# FM33FH0XX register map
File version: 1.0
CPU: SC000 r1p0, little endian, no MPU, no FPU, 3 interrupt priority bits
Registers are 32-bit, read-write, reset 0x0 unless marked. A register's access mark holds for its fields unless they carry their own. Offsets are from the block's base; lines under a group give offsets from that group; [hi:lo] are bit positions; {n}, {i} and the like mark numbered series; 'fields as' and 'values as' point back to an identical list; <NAME> marks a mode.

## Memory map
0x40000000 SCU size 0xC — SCU module information
0x40000400 DMA size 0x314 — DMA module information
0x40000800 QSPI size 0x30 — QSPI module information
0x40000C00 GPIOA size 0x30 — GPIOA module information
0x40000C40 GPIOB size 0x30 — GPIOB module information
0x40000C80 GPIOC size 0x30 — GPIOC module information
0x40000CC0 GPIOD size 0x30 — GPIOD module information
0x40000D00 GPIOE size 0x30 — GPIOE module information
0x40000D40 GPIOF size 0x30 — GPIOF module information
0x40000D80 GPIOG size 0x30 — GPIOG module information
0x40000DC0 GPIOH size 0x30 — GPIOH module information
0x40000E40 GPIO_COMMON size 0xE0 — GPIO module information
0x40001000 FLS size 0xA0 — FLS module information
0x40002000 PMU size 0x54 — PMU module information
0x40002400 CMU size 0x88 — CMU module information
0x40002800 RMU size 0x24 — RMU module information
0x40002C00 SFU size 0x10 — SFU module information
0x40010000 TSI size 0x80 — TSI module information
0x40010400 LPUART size 0x1C — LPUART module information
0x40010800 SPI2 size 0x28 — SPI2 module information
0x40011000 RTC size 0x44 — RTC module information
0x40011400 IWDT size 0x18 — IWDT module information
0x40011800 WWDT size 0x18 — WWDT module information
0x40011C00 UART0 size 0x84 — UART0 module information
0x40012000 UART1 size 0x84 — UART1 module information
0x40012C00 DAC size 0x20 — DAC module information
0x40013400 LPTIM16 size 0x28 — LPT16 module information
0x40013C00 TAU0 size 0xF0 — TAU0 module information
0x40013C00 TAU1 size 0x1D0 — TAU1 module information
0x40014800 SENT0 size 0x20 — SENT0 module information
0x40014C00 SENT1 size 0x20 — SENT1 module information
0x40015000 I2C0 size 0x24 — I2C0 module information
0x40015400 I2C1 size 0x24 — I2C1 module information
0x40016000 INTMUX size 0x8 — INTMUX module information
0x40017400 UART2 size 0x84 — UART2 module information
0x40017800 UART3 size 0x84 — UART3 module information
0x40017C00 UARTIR size 0x4 — UARTIR module information
0x40018000 CRC size 0x20 — CRC module information
0x40018C00 SPI1 size 0x28 — SPI1 module information
0x40019000 SPI0 size 0x28 — SPI0 module information
0x40019C00 COMP size 0x1C — COMP module information
0x4001A000 UART4 size 0x84 — UART4 module information
0x4001A400 UART5 size 0x84 — UART5 module information
0x4001A800 SVD size 0x14 — SVD module information
0x4001AC00 ADC size 0x108 — ADC module information
0x4001B000 ATIM size 0x100 — ATIM module information
0x4001B400 BSTIM16 size 0x30 — BSTIM16 module information
0x4001B800 UART6 size 0x54 — UART6 module information
0x4001BC00 UART7 size 0x54 — UART7 module information
0x4001C000 CLM0 size 0x1C — CLM0 module information
0x4001C400 CLM1 size 0x1C — CLM1 module information
0x4001C800 CLM2 size 0x1C — CLM2 module information
0x40020000 FDCAN size 0x748 — FDCAN module information

## Interrupts
{n} MUX{n} (INTMUX) (n=0..31) — MUX{n} interrupt

## ADC — ADC module information
Base 0x4001AC00
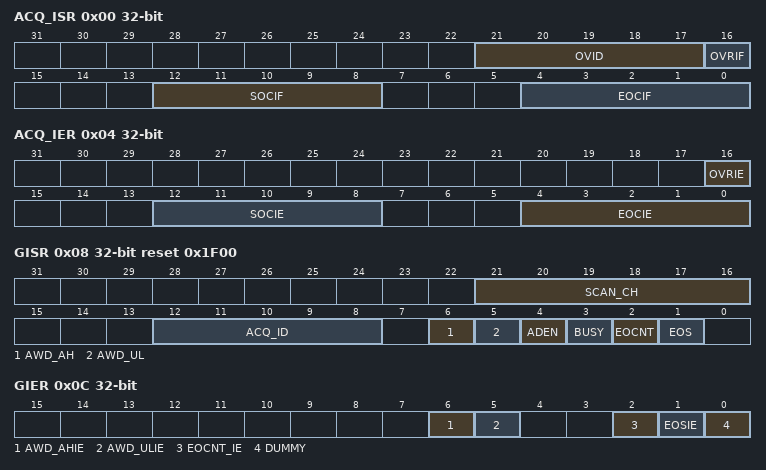
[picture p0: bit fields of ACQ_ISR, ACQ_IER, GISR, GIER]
0x00 ACQ_ISR
  [21:17] OVID ro — OVID field description
  [16] OVRIF — OVRIF field description
  [12:8] SOCIF — SOCIF field description
  [4:0] EOCIF — EOCIF field description
0x04 ACQ_IER
  [16] OVRIE — OVRIE field description
  [12:8] SOCIE — SOCIE field description
  [4:0] EOCIE — EOCIE field description
0x08 GISR reset 0x1F00
  [21:16] SCAN_CH ro — SCAN_CH field description
  [12:8] ACQ_ID ro — ACQ_ID field description
  [6] AWD_AH ro — AWD_AH field description
  [5] AWD_UL ro — AWD_UL field description
  [4] ADEN ro — ADEN field description
  [3] BUSY ro — BUSY field description
  [2] EOCNT ro — EOCNT field description
  [1] EOS ro — EOS field description
0x0C GIER
  [6] AWD_AHIE — AWD_AHIE field description
  [5] AWD_ULIE — AWD_ULIE field description
  [2] EOCNT_IE — EOCNT_IE field description
  [1] EOSIE — EOSIE field description
  [0] DUMMY — DUMMY field description
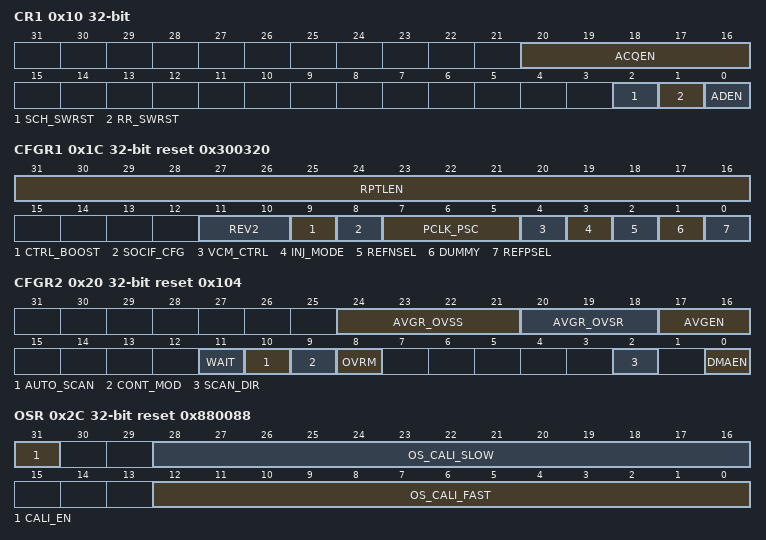
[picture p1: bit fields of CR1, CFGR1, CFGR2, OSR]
0x10 CR1
  [20:16] ACQEN — ACQEN field description
  [2] SCH_SWRST wo — SCH_SWRST field description
  [1] RR_SWRST wo — RR_SWRST field description
  [0] ADEN — ADEN field description
0x14 CR2
  [4:0] SWTRIG wo — SWTRIG field description
0x1C CFGR1 reset 0x300320
  [31:16] RPTLEN — RPTLEN field description
  [11:10] REV2 — REV2 field description
  [9] CTRL_BOOST — CTRL_BOOST field description
  [8] SOCIF_CFG — SOCIF_CFG field description
  [7:5] PCLK_PSC — PCLK_PSC field description
  [4] VCM_CTRL — VCM_CTRL field description
  [3] INJ_MODE — INJ_MODE field description
  [2] REFNSEL — REFNSEL field description
  [1] DUMMY — DUMMY field description
  [0] REFPSEL — REFPSEL field description
0x20 CFGR2 reset 0x104
  [24:21] AVGR_OVSS — AVGR_OVSS field description
  [20:18] AVGR_OVSR — AVGR_OVSR field description
  [17:16] AVGEN — AVGEN field description
  [11] WAIT — WAIT field description
  [10] AUTO_SCAN — AUTO_SCAN field description
  [9] CONT_MOD — CONT_MOD field description
  [8] OVRM — OVRM field description
  [2] SCAN_DIR — SCAN_DIR field description
  [0] DMAEN — DMAEN field description
0x2C OSR reset 0x880088
  [31] CALI_EN — CALI_EN field description
  [28:16] OS_CALI_SLOW — OS_CALI_SLOW field description
  [12:0] OS_CALI_FAST — OS_CALI_FAST field description
0x30 ACQ_SR
  [4:0] REQ ro — REQ field description
0x34 ACQ_SACR
  [31:0] CHEN — CHEN field description
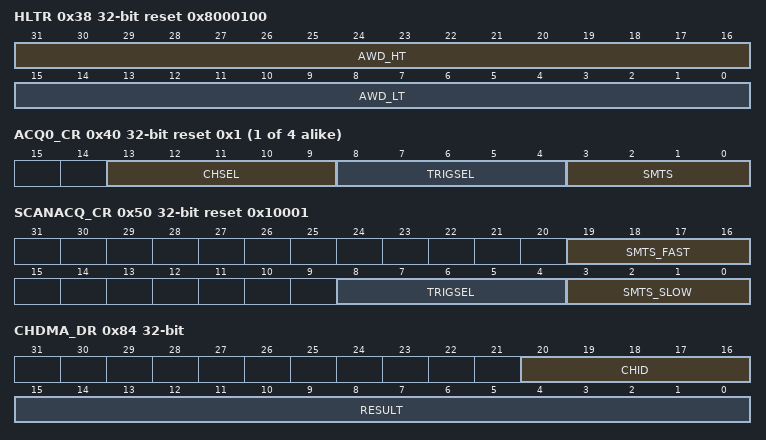
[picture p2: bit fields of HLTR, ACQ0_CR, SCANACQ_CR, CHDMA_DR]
0x38 HLTR reset 0x8000100
  [31:16] AWD_HT — AWD_HT field description
  [15:0] AWD_LT — AWD_LT field description
0x3C AWDCR
  [31:0] CHEN — CHEN field description
{0x40+4i} ACQ{i}_CR reset 0x1 (i=0..3)
  [13:9] CHSEL — CHSEL field description
  [8:4] TRIGSEL — TRIGSEL field description
  [3:0] SMTS — SMTS field description
0x50 SCANACQ_CR reset 0x10001
  [19:16] SMTS_FAST — SMTS_FAST field description
  [8:4] TRIGSEL — TRIGSEL field description
  [3:0] SMTS_SLOW — SMTS_SLOW field description
0x80 CHISR
  [31:0] IF — IF field description
0x84 CHDMA_DR
  [20:16] CHID ro — CHID field description
  [15:0] RESULT ro — RESULT field description
{0x88+4i} ACQ{i}DR (i=0..31)
  [15:0] RESULT ro — RESULT field description
